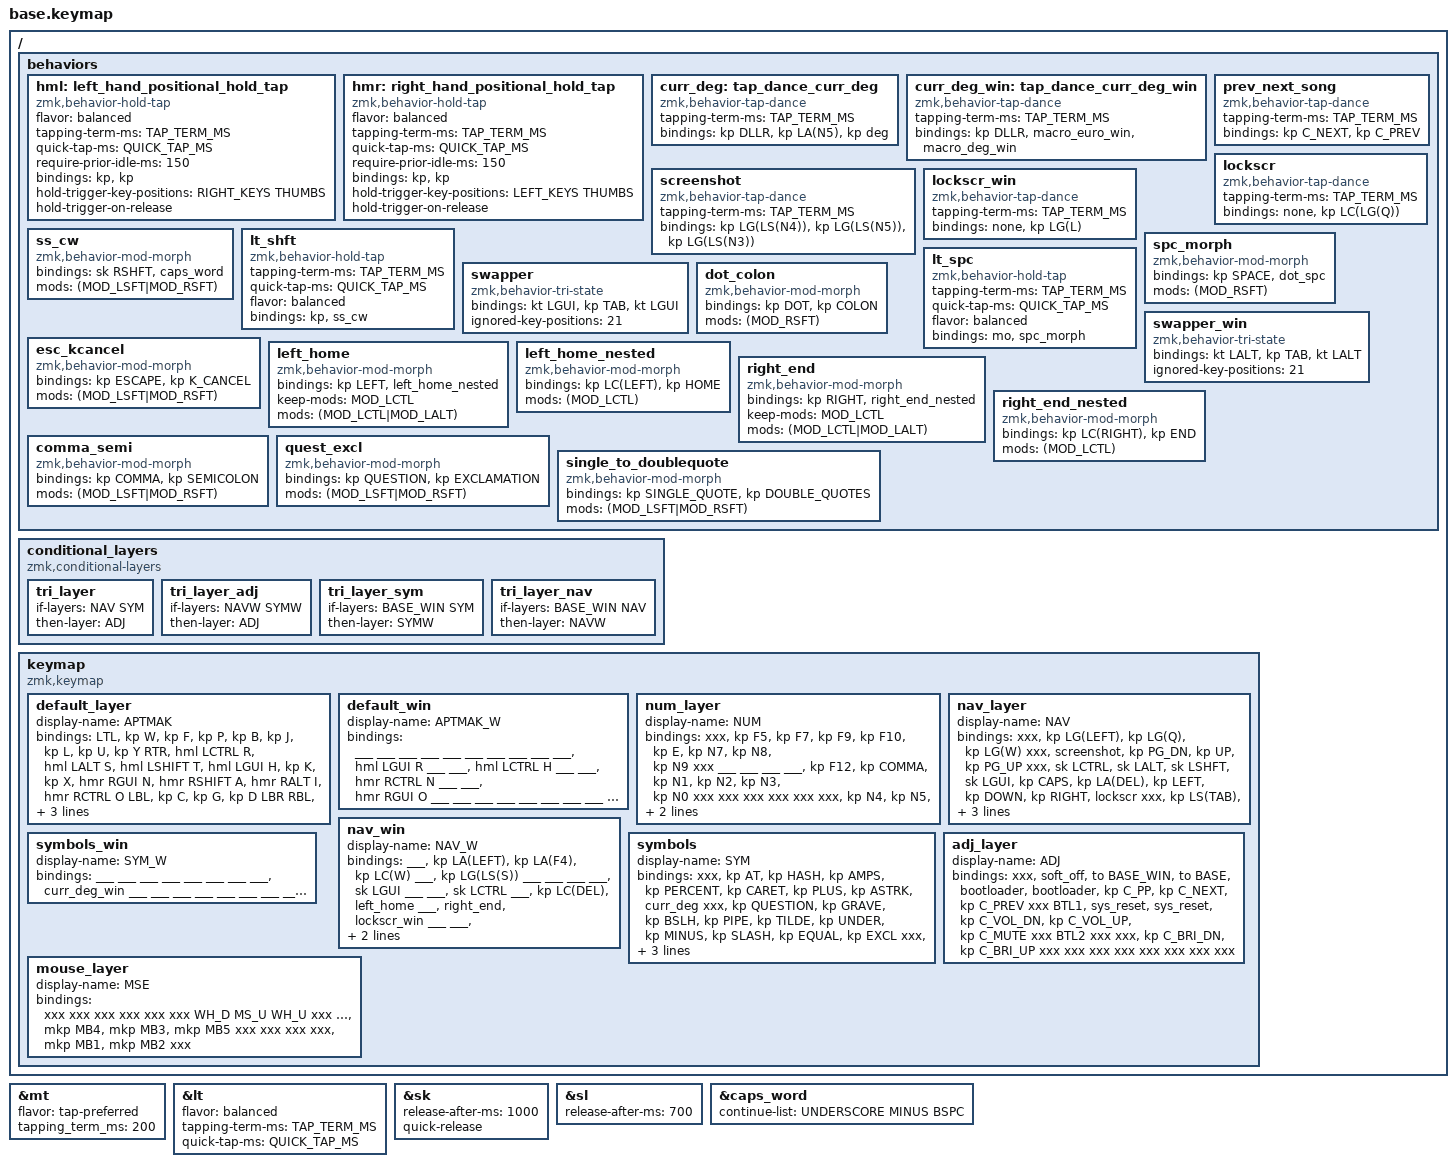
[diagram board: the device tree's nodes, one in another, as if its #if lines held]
#include <behaviors.dtsi>
#include <dt-bindings/zmk/keys.h>
#include <dt-bindings/zmk/outputs.h>


// layers ID definition
#define BASE 0
#define BASE_WIN 1
#define NUM 2
#define NAV 3
#define NAVW 4
#define SYM 5
#define SYMW 6
#define ADJ 7
#define MSE 8

#define xxx &none
#define ___ &trans

#include "common/combos.dtsi"
#include "common/extra_keys.h"
#if WIRELESS
    #include <dt-bindings/zmk/bt.h>
    #define BTL1  &bt BT_CLR   &bt BT_SEL 2  &pc_connect   &osx_connect
    #define BTL2  xxx          &bt BT_SEL 4  &bt BT_SEL 3  &out OUT_TOG
#else
    #define BTL1  xxx   xxx   xxx   xxx
    #define BTL2  xxx   xxx   xxx   xxx
#endif
#include "common/macros.dtsi"

#ifdef MOUSE_KEYS
    #include "common/mouse.dtsi"
#endif

// tapping term definition
#define TAP_TERM_MS 200
#define QUICK_TAP_MS 125

// macros definition
#define meh LG(LC(LALT))
#define hyper LG(LC(LS(LALT)))
#define deg RA(LS(N8))
#define HR_APP LG(LS(SPACE))
#define DSK_PREV_W LG(LC(LEFT))
#define DSK_NEXT_W LG(LC(RIGHT))

// OSX specific macros
#define undo LG(Z)
#define redo LG(LS(Z))
#define DSK_PREV LC(LEFT)
#define DSK_NEXT LC(RIGHT)
#define prev_win LG(TAB)
#define next_win LG(LS(TAB))

// 36 keys physical layout
#define LEFT_KEYS 0 1 2 3 4 10 11 12 13 14 20 21 22 23 24 // left-hand keys
#define RIGHT_KEYS 5 6 7 8 9 15 16 17 18 19 25 26 27 28 29 // right-hand keys
#define THUMBS 30 31 32 33 34 35 // thumb keys

// tune mod tap
&mt {
    flavor = "tap-preferred";
    tapping_term_ms = <200>;
};

// layer tap config
&lt {
    flavor = "balanced";
    tapping-term-ms = <TAP_TERM_MS>;
    quick-tap-ms = <QUICK_TAP_MS>;      // double-tap + hold repeats tap-key
};

// tune sticky key
&sk {
    release-after-ms = <1000>;
    quick-release;
};

// sticky layer config
&sl {
    release-after-ms = <700>;
};

// caps word settings
&caps_word {
    continue-list = <UNDERSCORE MINUS BSPC>;
};


// main tree
/ {
    behaviors {
        // HOME ROW MODS
        hml: left_hand_positional_hold_tap {
            compatible = "zmk,behavior-hold-tap";
            #binding-cells = <2>;
            flavor = "balanced";
            tapping-term-ms = <TAP_TERM_MS>;
            quick-tap-ms = <QUICK_TAP_MS>;       // double-tap + hold repeats tap-key
            require-prior-idle-ms = <150>;       // do not activate HOLD during typing flow
            bindings = <&kp>, <&kp>;
            hold-trigger-key-positions = <RIGHT_KEYS THUMBS>;
            hold-trigger-on-release;
        };

        hmr: right_hand_positional_hold_tap {
            compatible = "zmk,behavior-hold-tap";
            #binding-cells = <2>;
            flavor = "balanced";
            tapping-term-ms = <TAP_TERM_MS>;
            quick-tap-ms = <QUICK_TAP_MS>;       // double-tap + hold repeats tap-key
            require-prior-idle-ms = <150>;       // do not activate HOLD during typing flow
            bindings = <&kp>, <&kp>;
            hold-trigger-key-positions = <LEFT_KEYS THUMBS>;
            hold-trigger-on-release;
        };

        // TAP DANCES
        curr_deg: tap_dance_curr_deg {
            compatible = "zmk,behavior-tap-dance";
            #binding-cells = <0>;
            tapping-term-ms = <TAP_TERM_MS>;
            bindings = <&kp DLLR>, <&kp LA(N5)>, <&kp deg>;
        };
        curr_deg_win: tap_dance_curr_deg_win {
            compatible = "zmk,behavior-tap-dance";
            #binding-cells = <0>;
            tapping-term-ms = <TAP_TERM_MS>;
            bindings = <&kp DLLR>, <&macro_euro_win>, <&macro_deg_win>;
        };
        prev_next_song: prev_next_song {
            compatible = "zmk,behavior-tap-dance";
            #binding-cells = <0>;
            tapping-term-ms = <TAP_TERM_MS>;
            bindings = <&kp C_NEXT>, <&kp C_PREV>;
        };
        screenshot: screenshot {
            // single-tap: area selector, double-tap: open screenshot app, triple-tap: full-screen
            compatible = "zmk,behavior-tap-dance";
            #binding-cells = <0>;
            tapping-term-ms = <TAP_TERM_MS>;
            bindings = <&kp LG(LS(N4))>, <&kp LG(LS(N5))>, <&kp LG(LS(N3))>;
        };
        lockscr: lockscr {
            compatible = "zmk,behavior-tap-dance";
            #binding-cells = <0>;
            tapping-term-ms = <TAP_TERM_MS>;
            bindings = <&none>, <&kp LC(LG(Q))>;
        };
        lockscr_win: lockscr_win {
            compatible = "zmk,behavior-tap-dance";
            #binding-cells = <0>;
            tapping-term-ms = <TAP_TERM_MS>;
            bindings = <&none>, <&kp LG(L)>;
        };

        // tap: sticky-shift | lshft + tap: caps-word | hold: set in keymap (HYPER)
        ss_cw: ss_cw {
            compatible = "zmk,behavior-mod-morph";
            #binding-cells = <0>;
            bindings = <&sk RSHFT>, <&caps_word>;
            mods = <(MOD_LSFT|MOD_RSFT)>;
        };
        lt_shft: lt_shft {
            compatible = "zmk,behavior-hold-tap";
            #binding-cells = <2>;
            tapping-term-ms = <TAP_TERM_MS>;
            quick-tap-ms = <QUICK_TAP_MS>;
            flavor = "balanced";
            bindings = <&kp>, <&ss_cw>;
        };

        // tap: space | shft + tap: dot -> space -> sticky shift | hold: activate layer
        spc_morph: spc_morph {
            compatible = "zmk,behavior-mod-morph";
            #binding-cells = <0>;
            bindings = <&kp SPACE>, <&dot_spc>;
            mods = <(MOD_RSFT)>;
        };
        lt_spc: lt_spc {
            compatible = "zmk,behavior-hold-tap";
            #binding-cells = <2>;
            tapping-term-ms = <TAP_TERM_MS>;
            quick-tap-ms = <QUICK_TAP_MS>;
            flavor = "balanced";
            bindings = <&mo>, <&spc_morph>;
        };

        // Alt+Tab swapper, requires PR #1366
        swapper: swapper{
            compatible = "zmk,behavior-tri-state";
            #binding-cells = <0>;
            bindings = <&kt LGUI>, <&kp TAB>, <&kt LGUI>;
            ignored-key-positions = <21>;
        };

        swapper_win: swapper_win{
            compatible = "zmk,behavior-tri-state";
            #binding-cells = <0>;
            bindings = <&kt LALT>, <&kp TAB>, <&kt LALT>;
            ignored-key-positions = <21>;
        };

        //usefull mod-morphs
        esc_kcancel: esc_kcancel {
            compatible = "zmk,behavior-mod-morph";
            #binding-cells = <0>;
            bindings = <&kp ESCAPE>, <&kp K_CANCEL>;
            mods = <(MOD_LSFT|MOD_RSFT)>;
        };
        dot_colon: dot_colon {
            compatible = "zmk,behavior-mod-morph";
            #binding-cells = <0>;
            bindings = <&kp DOT>, <&kp COLON>;
            mods = <(MOD_RSFT)>;
        };
        left_home: left_home {
            compatible = "zmk,behavior-mod-morph";
            #binding-cells = <0>;
            bindings = <&kp LEFT>, <&left_home_nested>;
            keep-mods = <MOD_LCTL>;
            mods = <(MOD_LCTL|MOD_LALT)>;
        };
        left_home_nested: left_home_nested {
            compatible = "zmk,behavior-mod-morph";
            #binding-cells = <0>;
            bindings = <&kp LC(LEFT)>, <&kp HOME>;
            mods = <(MOD_LCTL)>;
        };
        right_end: right_end {
            compatible = "zmk,behavior-mod-morph";
            #binding-cells = <0>;
            bindings = <&kp RIGHT>, <&right_end_nested>;
            keep-mods = <MOD_LCTL>;
            mods = <(MOD_LCTL|MOD_LALT)>;
        };
        right_end_nested: right_end_nested {
            compatible = "zmk,behavior-mod-morph";
            #binding-cells = <0>;
            bindings = <&kp LC(RIGHT)>, <&kp END>;
            mods = <(MOD_LCTL)>;
        };
        comma_semi: comma_semi {
            compatible = "zmk,behavior-mod-morph";
            #binding-cells = <0>;
            bindings = <&kp COMMA>, <&kp SEMICOLON>;
            mods = <(MOD_LSFT|MOD_RSFT)>;
        };
        quest_excl: quest_excl {
            compatible = "zmk,behavior-mod-morph";
            #binding-cells = <0>;
            bindings = <&kp QUESTION>, <&kp EXCLAMATION>;
            mods = <(MOD_LSFT|MOD_RSFT)>;
        };
        single_to_doublequote: single_to_doublequote {
            compatible = "zmk,behavior-mod-morph";
            #binding-cells = <0>;
            bindings = <&kp SINGLE_QUOTE>, <&kp DOUBLE_QUOTES>;
            mods = <(MOD_LSFT|MOD_RSFT)>;
        };
    };

    conditional_layers {
        compatible = "zmk,conditional-layers";
        tri_layer {
            if-layers = <NAV SYM>;
            then-layer = <ADJ>;
        };
        tri_layer_adj {
            if-layers = <NAVW SYMW>;
            then-layer = <ADJ>;
        };
        tri_layer_sym {
            if-layers = <BASE_WIN SYM>;
            then-layer = <SYMW>;
        };
        tri_layer_nav {
            if-layers = <BASE_WIN NAV>;
            then-layer = <NAVW>;
        };
    };

    keymap {
        compatible = "zmk,keymap";

        default_layer {
            display-name = "APTMAK";
            bindings = <
             //╭──────────────┬──────────────┬──────────────┬──────────────┬──────────────╮     ╭──────────────┬──────────────┬──────────────┬──────────────┬──────────────╮
                LTL            &kp W          &kp F          &kp P          &kp B                &kp J          &kp L          &kp U          &kp Y          RTR
             //├──────────────┼──────────────┼──────────────┼──────────────┼──────────────┤     ├──────────────┼──────────────┼──────────────┼──────────────┼──────────────┤
                &hml LCTRL R   &hml LALT S    &hml LSHIFT T  &hml LGUI H    &kp K                &kp X          &hmr RGUI N    &hmr RSHIFT A  &hmr RALT I    &hmr RCTRL O
             //├──────────────┼──────────────┼──────────────┼──────────────┼──────────────┤     ├──────────────┼──────────────┼──────────────┼──────────────┼──────────────┤
                LBL            &kp C          &kp G          &kp D          LBR                  RBL            &kp M          &comma_semi    &dot_colon     RBR
             //╰──────────────┴──────────────┼──────────────┼──────────────┼──────────────┤     ├──────────────┼──────────────┼──────────────┼──────────────┴──────────────╯
                                              xxx            &lt NUM RET    &lt_spc NAV 0        &lt SYM E      &lt_shft meh 0 xxx
             //                              ╰──────────────┴──────────────┴──────────────╯     ╰──────────────┴──────────────┴──────────────╯
            >;
        };

        default_win {
            display-name = "APTMAK_W";
            bindings = <
             //╭──────────────┬──────────────┬──────────────┬──────────────┬──────────────╮     ╭──────────────┬──────────────┬──────────────┬──────────────┬──────────────╮
                ___            ___            ___            ___            ___                  ___            ___            ___            ___            ___
             //├──────────────┼──────────────┼──────────────┼──────────────┼──────────────┤     ├──────────────┼──────────────┼──────────────┼──────────────┼──────────────┤
                &hml LGUI R    ___            ___            &hml LCTRL H   ___                  ___            &hmr RCTRL N   ___            ___            &hmr RGUI O
             //├──────────────┼──────────────┼──────────────┼──────────────┼──────────────┤     ├──────────────┼──────────────┼──────────────┼──────────────┼──────────────┤
                ___            ___            ___            ___            ___                  ___            ___            ___            ___            ___
             //╰──────────────┴──────────────┼──────────────┼──────────────┼──────────────┤     ├──────────────┼──────────────┼──────────────┼──────────────┴──────────────╯
                                              ___            ___            ___                  ___            ___            ___
             //                              ╰──────────────┴──────────────┴──────────────╯     ╰──────────────┴──────────────┴──────────────╯
            >;
        };

        num_layer{
            display-name = "NUM";
            bindings = <
             //╭──────────────┬──────────────┬──────────────┬──────────────┬──────────────╮     ╭──────────────┬──────────────┬──────────────┬──────────────┬──────────────╮
                xxx            &kp F5         &kp F7         &kp F9         &kp F10              &kp E          &kp N7         &kp N8         &kp N9         xxx
             //├──────────────┼──────────────┼──────────────┼──────────────┼──────────────┤     ├──────────────┼──────────────┼──────────────┼──────────────┼──────────────┤
                ___            ___            ___            ___            &kp F12              &kp COMMA      &kp N1         &kp N2         &kp N3         &kp N0
             //├──────────────┼──────────────┼──────────────┼──────────────┼──────────────┤     ├──────────────┼──────────────┼──────────────┼──────────────┼──────────────┤
                xxx            xxx            xxx            xxx            xxx                  xxx            &kp N4         &kp N5         &kp N6         xxx
             //╰──────────────┴──────────────┼──────────────┼──────────────┼──────────────┤     ├──────────────┼──────────────┼──────────────┼──────────────┴──────────────╯
                                              xxx            xxx            ___                  &lt SYM SPACE  &kp DOT        xxx
             //                              ╰──────────────┴──────────────┴──────────────╯     ╰──────────────┴──────────────┴──────────────╯
            >;
        };

        nav_layer{
            display-name = "NAV";
            bindings = <
             //╭──────────────┬──────────────┬──────────────┬──────────────┬──────────────╮     ╭──────────────┬──────────────┬──────────────┬──────────────┬──────────────╮
                xxx            &kp LG(LEFT)   &kp LG(Q)      &kp LG(W)      xxx                  &screenshot    &kp PG_DN      &kp UP         &kp PG_UP      xxx
             //├──────────────┼──────────────┼──────────────┼──────────────┼──────────────┤     ├──────────────┼──────────────┼──────────────┼──────────────┼──────────────┤
                &sk LCTRL      &sk LALT       &sk LSHFT      &sk LGUI       &kp CAPS             &kp LA(DEL)    &kp LEFT       &kp DOWN       &kp RIGHT      &lockscr
             //├──────────────┼──────────────┼──────────────┼──────────────┼──────────────┤     ├──────────────┼──────────────┼──────────────┼──────────────┼──────────────┤
                xxx            &kp LS(TAB)    &swapper       &kp LC(TAB)    xxx                  xxx            &kp DSK_PREV   &kp HR_APP     &kp DSK_NEXT   xxx
             //╰──────────────┴──────────────┼──────────────┼──────────────┼──────────────┤     ├──────────────┼──────────────┼──────────────┼──────────────┴──────────────╯
                                              xxx            xxx            ___                  ___            xxx            xxx
             //                              ╰──────────────┴──────────────┴──────────────╯     ╰──────────────┴──────────────┴──────────────╯
            >;
        };

        nav_win{
            display-name = "NAV_W";
            bindings = <
             //╭──────────────┬──────────────┬──────────────┬──────────────┬──────────────╮     ╭──────────────┬──────────────┬──────────────┬──────────────┬──────────────╮
                ___            &kp LA(LEFT)   &kp LA(F4)     &kp LC(W)      ___                  &kp LG(LS(S))  ___            ___            ___            ___
             //├──────────────┼──────────────┼──────────────┼──────────────┼──────────────┤     ├──────────────┼──────────────┼──────────────┼──────────────┼──────────────┤
                &sk LGUI       ___            ___            &sk LCTRL      ___                  &kp LC(DEL)    &left_home     ___            &right_end     &lockscr_win
             //├──────────────┼──────────────┼──────────────┼──────────────┼──────────────┤     ├──────────────┼──────────────┼──────────────┼──────────────┼──────────────┤
                ___            ___            &swapper_win   ___            ___                  ___            &kp DSK_PREV_W ___            &kp DSK_NEXT_W ___
             //╰──────────────┴──────────────┼──────────────┼──────────────┼──────────────┤     ├──────────────┼──────────────┼──────────────┼──────────────┴──────────────╯
                                              xxx            ___            ___                  ___            ___            xxx
             //                              ╰──────────────┴──────────────┴──────────────╯     ╰──────────────┴──────────────┴──────────────╯
            >;
        };

        symbols {
            display-name = "SYM";
            bindings = <
             //╭──────────────┬──────────────┬──────────────┬──────────────┬──────────────╮     ╭──────────────┬──────────────┬──────────────┬──────────────┬──────────────╮
                xxx            &kp AT         &kp HASH       &kp AMPS       &kp PERCENT          &kp CARET      &kp PLUS       &kp ASTRK      &curr_deg      xxx
             //├──────────────┼──────────────┼──────────────┼──────────────┼──────────────┤     ├──────────────┼──────────────┼──────────────┼──────────────┼──────────────┤
                &kp QUESTION   &kp GRAVE      &kp BSLH       &kp PIPE       &kp TILDE            &kp UNDER      &kp MINUS      &kp SLASH      &kp EQUAL      &kp EXCL
             //├──────────────┼──────────────┼──────────────┼──────────────┼──────────────┤     ├──────────────┼──────────────┼──────────────┼──────────────┼──────────────┤
                xxx            &kp RA(GRAVE)  &kp RA(E)      &kp LT         xxx                  xxx            &kp GT         &kp SEMI       &kp COLON      xxx
             //╰──────────────┴──────────────┼──────────────┼──────────────┼──────────────┤     ├──────────────┼──────────────┼──────────────┼──────────────┴──────────────╯
                                              xxx            ___            ___                  ___            xxx            xxx
             //                              ╰──────────────┴──────────────┴──────────────╯     ╰──────────────┴──────────────┴──────────────╯
            >;
        };

        symbols_win {
            display-name = "SYM_W";
            bindings = <
             //╭──────────────┬──────────────┬──────────────┬──────────────┬──────────────╮     ╭──────────────┬──────────────┬──────────────┬──────────────┬──────────────╮
                ___            ___            ___            ___            ___                  ___            ___            ___            &curr_deg_win  ___
             //├──────────────┼──────────────┼──────────────┼──────────────┼──────────────┤     ├──────────────┼──────────────┼──────────────┼──────────────┼──────────────┤
                ___            ___            ___            ___            ___                  ___            ___            ___            ___            ___
             //├──────────────┼──────────────┼──────────────┼──────────────┼──────────────┤     ├──────────────┼──────────────┼──────────────┼──────────────┼──────────────┤
                ___            ___            ___            ___            ___                  ___            ___            ___            ___            ___
             //╰──────────────┴──────────────┼──────────────┼──────────────┼──────────────┤     ├──────────────┼──────────────┼──────────────┼──────────────┴──────────────╯
                                              xxx            ___            ___                  ___            ___            xxx
             //                              ╰──────────────┴──────────────┴──────────────╯     ╰──────────────┴──────────────┴──────────────╯
            >;
        };

        adj_layer {
            display-name = "ADJ";
            bindings = <
             //╭──────────────┬──────────────┬──────────────┬──────────────┬──────────────╮     ╭──────────────┬──────────────┬──────────────┬──────────────┬──────────────╮
                xxx            &soft_off      &to BASE_WIN   &to BASE       &bootloader          &bootloader    &kp C_PP       &kp C_NEXT     &kp C_PREV     xxx
             //├──────────────┼──────────────┼──────────────┼──────────────┼──────────────┤     ├──────────────┼──────────────┼──────────────┼──────────────┼──────────────┤
                BTL1                                                        &sys_reset           &sys_reset     &kp C_VOL_DN   &kp C_VOL_UP   &kp C_MUTE     xxx
             //├──────────────┼──────────────┼──────────────┼──────────────┼──────────────┤     ├──────────────┼──────────────┼──────────────┼──────────────┼──────────────┤
                BTL2                                                        xxx                  xxx            &kp C_BRI_DN   &kp C_BRI_UP   xxx            xxx
             //╰──────────────┴──────────────┼──────────────┼──────────────┼──────────────┤     ├──────────────┼──────────────┼──────────────┼──────────────┴──────────────╯
                                              xxx            xxx            xxx                  xxx            xxx            xxx
             //                              ╰──────────────┴──────────────┴──────────────╯     ╰──────────────┴──────────────┴──────────────╯
            >;
        };

        #ifdef MOUSE_KEYS
        mouse_layer {
            display-name = "MSE";
            bindings = <
             //╭──────────────┬──────────────┬──────────────┬──────────────┬──────────────╮     ╭──────────────┬──────────────┬──────────────┬──────────────┬──────────────╮
                xxx            xxx            xxx            xxx            xxx                  xxx            WH_D           MS_U           WH_U           xxx
             //├──────────────┼──────────────┼──────────────┼──────────────┼──────────────┤     ├──────────────┼──────────────┼──────────────┼──────────────┼──────────────┤
                ___            ___            ___            ___            xxx                  WH_L           MS_L           MS_D           MS_R           WH_R
             //├──────────────┼──────────────┼──────────────┼──────────────┼──────────────┤     ├──────────────┼──────────────┼──────────────┼──────────────┼──────────────┤
                xxx            xxx            xxx            xxx            xxx                  xxx            &mkp MB4       &mkp MB3       &mkp MB5       xxx
             //╰──────────────┴──────────────┼──────────────┼──────────────┼──────────────┤     ├──────────────┼──────────────┼──────────────┼──────────────┴──────────────╯
                                              xxx            xxx            xxx                  &mkp MB1       &mkp MB2       xxx
             //                              ╰──────────────┴──────────────┴──────────────╯     ╰──────────────┴──────────────┴──────────────╯
            >;
        };
        #endif

    };
};
